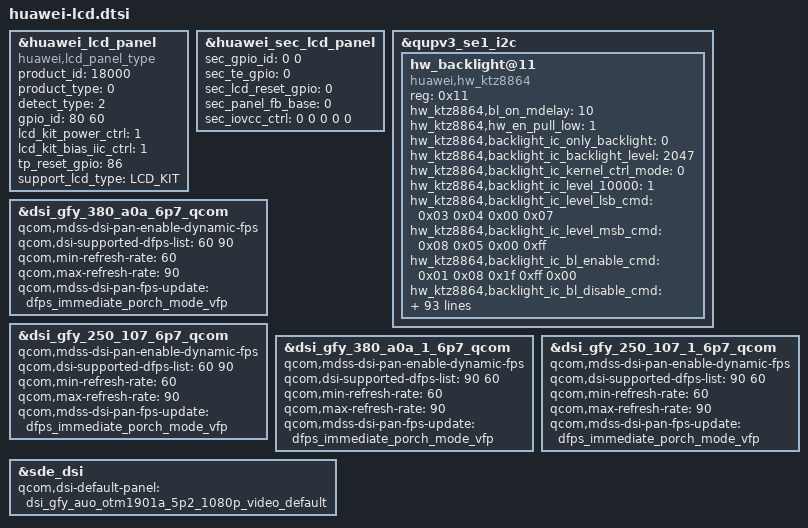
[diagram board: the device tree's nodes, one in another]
#include "../../../lcdkit3.0/gfy/devkit_lcd_kit.dtsi"
&huawei_lcd_panel {
	compatible = "huawei,lcd_panel_type";
	/* auto_key_info @ name: product_id type: uint32 default: 0 */
	product_id = <18000>;
	/* auto_key_info @ name: product_type type: uint32 default: 0 */
	product_type = <0>;
	detect_type = <2>;
	/* auto_key_info @ name: gpio_id[2] type: int default: 0 */
	gpio_id = <80 60>;
	/* auto_key_info @ name: lcd_kit_power_ctrl type: uint32 default: 0 */
	lcd_kit_power_ctrl = <1>;
	/* auto_key_info @ name: lcd_kit_bias_iic_ctrl type: uint32 default: 0 */
	lcd_kit_bias_iic_ctrl = <1>;
	/* auto_key_info @ name: tp_reset_gpio type: uint32 default: 0 */
	tp_reset_gpio = <86>;
	support_lcd_type = "LCD_KIT";
};

&huawei_sec_lcd_panel {
	/* auto_key_info @ name: sec_gpio_id[2] type: int default: 0 */
	sec_gpio_id = <0 0>;
	/* auto_key_info @ name: sec_te_gpio type: int default: 0 */
	sec_te_gpio = <0>;
	/* auto_key_info @ name: sec_lcd_reset_gpio type: int default: 0 */
	sec_lcd_reset_gpio = <0>;
	/* auto_key_info @ name: sec_panel_fb_base type: UINTN default: 0 */
	sec_panel_fb_base = <0>;
	/* auto_key_info @ name: sec_iovcc_ctrl[5] type: uint32 default: 0 */
	sec_iovcc_ctrl = <0 0 0 0 0>;
};

&qupv3_se1_i2c {
	hw_backlight@11 {
		status = "ok";
		compatible = "huawei,hw_ktz8864","huawei,hw_lm36274";
		reg = <0x11>;

		hw_ktz8864,bl_on_mdelay = <10>;
		hw_ktz8864,hw_en_pull_low = <1>;
		hw_ktz8864,backlight_ic_only_backlight = <0>;
		hw_ktz8864,backlight_ic_backlight_level = <2047>;
		hw_ktz8864,backlight_ic_kernel_ctrl_mode = <0>;
		hw_ktz8864,backlight_ic_level_10000 = <1>;
		hw_ktz8864,backlight_ic_level_lsb_cmd = <0x03 0x04 0x00 0x07>;
		hw_ktz8864,backlight_ic_level_msb_cmd = <0x08 0x05 0x00 0xff>;
		hw_ktz8864,backlight_ic_bl_enable_cmd = <0x01 0x08 0x1f 0xff 0x00>;
		hw_ktz8864,backlight_ic_bl_disable_cmd = <0x01 0x08 0x00 0xff 0x00>;
		hw_ktz8864,backlight_ic_dev_disable_cmd = <0x01 0x08 0x70 0xff 0x00>;
		hw_ktz8864,backlight_ic_pull_boost_support = <0>;
		hw_ktz8864,backlight_ic_pull_boost_delay = <0>;
		hw_ktz8864,backlight_ic_vsp_enable_cmd = <0x01 0x09 0x9c 0xff 0x00>;
		hw_ktz8864,backlight_ic_vsn_enable_cmd = <0x01 0x09 0x9e 0xff 0x00>;
		hw_ktz8864,backlight_ic_vsp_disable_cmd = <0x01 0x09 0x98 0xff 0x00>;
		hw_ktz8864,backlight_ic_vsn_disable_cmd = <0x01 0x09 0x9c 0xff 0x00>;
		hw_ktz8864,backlight_ic_pull_down_vsp_cmd = <0x01 0x0f 0x00 0xff 0x00>;
		hw_ktz8864,backlight_ic_pull_down_vsn_cmd = <0x01 0x0f 0x00 0xff 0x00>;
		hw_ktz8864,backlight_ic_pull_down_boost_cmd = <0x01 0x0f 0x00 0xff 0x00>;
		hw_ktz8864,backlight_ic_bias_enable_cmd = <0x01 0x00 0x00 0x00 0x00>;
		hw_ktz8864,backlight_ic_bias_disable_cmd = <0x01 0x00 0x00 0x00 0x00>;
		hw_ktz8864,backlight_ic_fault_check_support = <1>;
		hw_ktz8864,backlight_ic_ovp_flag_cmd = <0x00 0x0f 0x02 0x02 0x00>;
		hw_ktz8864,backlight_ic_ocp_flag_cmd = <0x00 0x0f 0x01 0x01 0x00>;
		hw_ktz8864,backlight_ic_tsd_flag_cmd = <0x00 0x0f 0x40 0x40 0x00>;
		hw_ktz8864,backlight_ic_kernel_init_cmd = <0x01 0x02 0x50 0xff 0x00
						0x01 0x03 0x85 0xff 0x00
						0x01 0x04 0x00 0xff 0x00
						0x01 0x05 0x00 0xff 0x00
						0x01 0x06 0x27 0xff 0x00
						0x01 0x07 0x3b 0xff 0x00
						0x01 0x0a 0x91 0xff 0x00
						0x01 0x0b 0x00 0xff 0x00
						0x01 0x0c 0x2e 0xff 0x00
						0x01 0x0d 0x28 0xff 0x00
						0x01 0x0e 0x28 0xff 0x00
						0x01 0x10 0x06 0xff 0x00
						0x01 0x11 0x76 0xff 0x00
						0x01 0x09 0x98 0xff 0x00
						0x01 0x08 0x17 0xff 0x00>;
		hw_ktz8864,backlight_ic_num_of_kernel_init_cmd = <15>;
		hw_ktz8864,backlight_ic_init_vsp_index = <9>;
		hw_ktz8864,backlight_ic_init_vsn_index = <10>;
		hw_ktz8864,dimming_support = <1>;
		hw_ktz8864,dimming_config = <0xD5>;
		hw_ktz8864,dimming_config_reg = <0x03>;
		hw_ktz8864,dimming_resume = <0x85>;

		hw_lm36274,bl_on_mdelay = <10>;
		hw_lm36274,hw_en_pull_low = <1>;
		hw_lm36274,backlight_ic_only_backlight = <0>;
		hw_lm36274,backlight_ic_backlight_level = <2047>;
		hw_lm36274,backlight_ic_kernel_ctrl_mode = <0>;
		hw_lm36274,backlight_ic_level_10000 = <1>;
		hw_lm36274,backlight_ic_level_lsb_cmd = <0x03 0x04 0x00 0x07>;
		hw_lm36274,backlight_ic_level_msb_cmd = <0x08 0x05 0x00 0xff>;
		hw_lm36274,backlight_ic_bl_enable_cmd = <0x01 0x08 0x1f 0xff 0x00>;
		hw_lm36274,backlight_ic_bl_disable_cmd = <0x01 0x08 0x00 0xff 0x00>;
		hw_lm36274,backlight_ic_dev_disable_cmd = <0x01 0x08 0x70 0xff 0x00>;
		hw_lm36274,backlight_ic_pull_boost_support = <0>;
		hw_lm36274,backlight_ic_pull_boost_delay = <0>;
		hw_lm36274,backlight_ic_vsp_enable_cmd = <0x01 0x09 0x9c 0xff 0x00>;
		hw_lm36274,backlight_ic_vsn_enable_cmd = <0x01 0x09 0x9e 0xff 0x00>;
		hw_lm36274,backlight_ic_vsp_disable_cmd = <0x01 0x09 0x98 0xff 0x00>;
		hw_lm36274,backlight_ic_vsn_disable_cmd = <0x01 0x09 0x9c 0xff 0x00>;
		hw_lm36274,backlight_ic_pull_down_vsp_cmd = <0x01 0x0f 0x00 0xff 0x00>;
		hw_lm36274,backlight_ic_pull_down_vsn_cmd = <0x01 0x0f 0x00 0xff 0x00>;
		hw_lm36274,backlight_ic_pull_down_boost_cmd = <0x01 0x0f 0x00 0xff 0x00>;
		hw_lm36274,backlight_ic_bias_enable_cmd = <0x01 0x00 0x00 0x00 0x00>;
		hw_lm36274,backlight_ic_bias_disable_cmd = <0x01 0x00 0x00 0x00 0x00>;
		hw_lm36274,backlight_ic_fault_check_support = <1>;
		hw_lm36274,backlight_ic_ovp_flag_cmd = <0x00 0x0f 0x02 0x02 0x00>;
		hw_lm36274,backlight_ic_ocp_flag_cmd = <0x00 0x0f 0x01 0x01 0x00>;
		hw_lm36274,backlight_ic_tsd_flag_cmd = <0x00 0x0f 0x40 0x40 0x00>;
		hw_lm36274,backlight_ic_kernel_init_cmd = <0x01 0x02 0x50 0xff 0x00
						0x01 0x03 0x85 0xff 0x00
						0x01 0x04 0x00 0xff 0x00
						0x01 0x05 0x00 0xff 0x00
						0x01 0x06 0x27 0xff 0x00
						0x01 0x07 0x3b 0xff 0x00
						0x01 0x0a 0x91 0xff 0x00
						0x01 0x0b 0x00 0xff 0x00
						0x01 0x0c 0x2e 0xff 0x00
						0x01 0x0d 0x28 0xff 0x00
						0x01 0x0e 0x28 0xff 0x00
						0x01 0x10 0x06 0xff 0x00
						0x01 0x11 0x76 0xff 0x00
						0x01 0x09 0x98 0xff 0x00
						0x01 0x08 0x17 0xff 0x00>;
		hw_lm36274,backlight_ic_num_of_kernel_init_cmd = <15>;
		hw_lm36274,backlight_ic_init_vsp_index = <9>;
		hw_lm36274,backlight_ic_init_vsn_index = <10>;
		hw_lm36274,dimming_support = <1>;
		hw_lm36274,dimming_config = <0xD5>;
		hw_lm36274,dimming_config_reg = <0x03>;
		hw_lm36274,dimming_resume = <0x85>;
	};
};

&dsi_gfy_380_a0a_6p7_qcom {
    qcom,mdss-dsi-pan-enable-dynamic-fps;
    qcom,dsi-supported-dfps-list = <60 90>;
    qcom,min-refresh-rate = <60>;
    qcom,max-refresh-rate = <90>;
    qcom,mdss-dsi-pan-fps-update = "dfps_immediate_porch_mode_vfp";
};
&dsi_gfy_250_107_6p7_qcom {
    qcom,mdss-dsi-pan-enable-dynamic-fps;
    qcom,dsi-supported-dfps-list = <60 90>;
    qcom,min-refresh-rate = <60>;
    qcom,max-refresh-rate = <90>;
    qcom,mdss-dsi-pan-fps-update = "dfps_immediate_porch_mode_vfp";
};
&dsi_gfy_380_a0a_1_6p7_qcom {
    qcom,mdss-dsi-pan-enable-dynamic-fps;
    qcom,dsi-supported-dfps-list = <90 60>;
    qcom,min-refresh-rate = <60>;
    qcom,max-refresh-rate = <90>;
    qcom,mdss-dsi-pan-fps-update = "dfps_immediate_porch_mode_vfp";
};
&dsi_gfy_250_107_1_6p7_qcom {
    qcom,mdss-dsi-pan-enable-dynamic-fps;
    qcom,dsi-supported-dfps-list = <90 60>;
    qcom,min-refresh-rate = <60>;
    qcom,max-refresh-rate = <90>;
    qcom,mdss-dsi-pan-fps-update = "dfps_immediate_porch_mode_vfp";
};

&sde_dsi {
	qcom,dsi-default-panel = <&dsi_gfy_auo_otm1901a_5p2_1080p_video_default>;
};
